# Display_Subsystem register map
Vendor: Texas Instruments
Peripheral module from a debugger description file (folder omap36xx).
Registers are 32-bit, read-only, reset 0x0 unless marked. A register's access mark holds for its fields unless they carry their own. Offsets are as the file gives them; lines under a group give offsets from that group; [hi:lo] are bit positions; {n}, {i} and the like mark numbered series; 'fields as' and 'values as' point back to an identical list; <NAME> marks a mode.

## Display_Subsystem
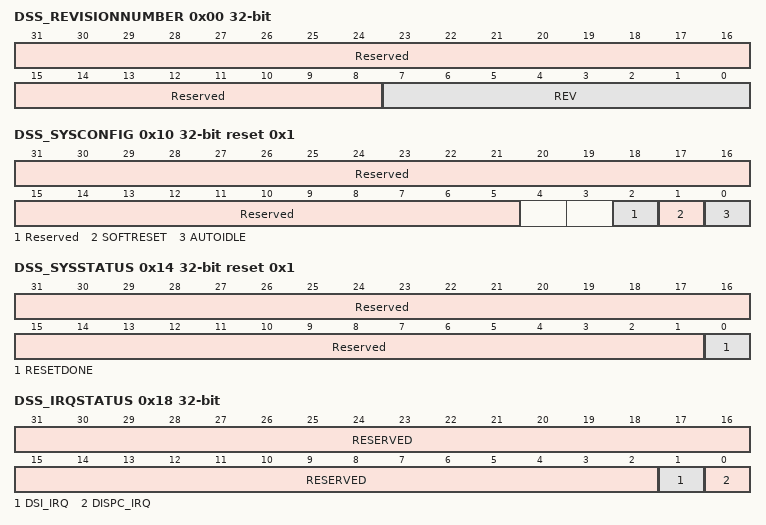
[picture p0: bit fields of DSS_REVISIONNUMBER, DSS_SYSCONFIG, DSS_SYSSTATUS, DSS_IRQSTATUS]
0x00 DSS_REVISIONNUMBER (reset mask 0xFFFFFF00) — This register contains the display subsystem revision number.
  [31:8] Reserved — Read returns 0.
  [7:0] REV — Revision number[7:4] Major revision[3:0] Minor revision
0x10 DSS_SYSCONFIG rw reset 0x1 — This register controls the various parameters of the interconnect interface.
  [31:5] Reserved — Write 0s for future compatibility. Reads return zero.
  [2] Reserved — Write 0s for future compatibility . Reads return zero.
  [1] SOFTRESET — Software reset. Set this bit to 1 to trigger a module reset. The bit is automatically reset by the hardware. During reads, it always returns 0.
    0=Normal mode; 1=The module is reset
  [0] AUTOIDLE — Enable power management capability
    0=OCP clock is free-running; 1=Automatic OCP clock gating strategy is applied based on the OCP interface activity
0x14 DSS_SYSSTATUS reset 0x1 — This register provides status information about the module.
  [31:1] Reserved — Read returns 0.
  [0] RESETDONE — Internal reset monitoring
    0=RESETDONE_0_r (Internal module reset is ongoing.); 1=RESETDONE_1_r (Reset completed)
0x18 DSS_IRQSTATUS — The register indicates the source of the interrupt and the status of the interrupt line.
  [31:2] RESERVED — Reads returns 0.
  [1] DSI_IRQ — DSI interrupt status (related toDSI_IRQSTATUS)
    0=DSI interrupt inactive; 1=DSI interrupt active
  [0] DISPC_IRQ — DISPC interrupt status (related toDISPC_IRQSTATUS)
    0=DISPC interrupt inactive; 1=DISPC interrupt active
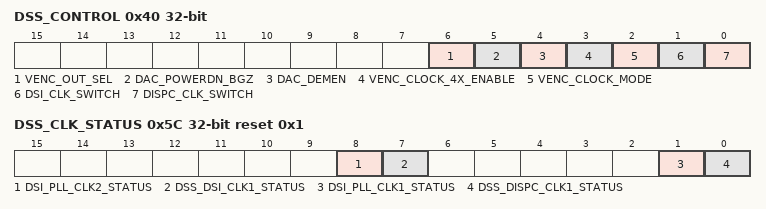
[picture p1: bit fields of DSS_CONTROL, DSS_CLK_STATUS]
0x40 DSS_CONTROL rw — This register contains the display subsystem control bits.
  [6] VENC_OUT_SEL — Video DAC1 input selection:0x0: CVBS VENC output selected for composite video mode0x1: Luminance VENC output selected for s-video mode
  [5] DAC_POWERDN_BGZ — DAC Power-Down Control0x0: DAC Power-Down Band Gap powered down0x1: DAC Power-Down Band Gap powered up
  [4] DAC_DEMEN — DAC dynamic element matching enable0x0: DAC Dynamic Element Matching Disabled 0x1: DAC Dynamic Element Matching Enabled
  [3] VENC_CLOCK_4X_ENABLE — VENC clock 4x enable0x0: Disable 0x1: Enable
  [2] VENC_CLOCK_MODE — VENC clock mode. See, . 0x0: Mode 0. All three balanced clocks, derived from the DSS_TV_CLK clock, are provided to the VENC, if the VENC_CLOCK_4X_ENABLE bit [3] is set to 1 by software. 0x1: Mode 1. The VENC_CLOCK_4X_ENABLE bit [3] is used to control clock gating.
  [1] DSI_CLK_SWITCH — Selects the clock source for the DSI functional clock0x0: DSS1_ALWON_FCLK clock is selected (from PRCM)0x1: DSI2_PLL_FCLK clock is selected (from DSI PLL)
  [0] DISPC_CLK_SWITCH — Selects the clock source for the DISPC functional clock0x0: DSS1_ALWON_FCLK clock is selected (from PRCM)0x1: DSI1_PLL_FCLK clock is selected (from DSI PLL)
0x5C DSS_CLK_STATUS reset 0x1 — This register contains the display subsystem register.
  [8] DSI_PLL_CLK2_STATUS — DSI2_PLL_FCLK clock selection status (DSI mux) Indicates if the DSI protocol engine is running from the DSI2_PLL_FCLK clockRead 0: DSI2_PLL_FCLK is not selected (unused by DSI).Read 1: DSI2_PLL_FCLK is selected (used by DSI).
  [7] DSS_DSI_CLK1_STATUS — DSS1_ALWON_FCLK clock selection status (DSI mux) Indicates if the DSI protocol engine is running from the DSS1_ALWON_FCLK clockRead 0: DSS1_ALWON_FCLK is not selected (unused by DSI).Read 1: DSS1_ALWON_FCLK is selected (used by DSI).
  [1] DSI_PLL_CLK1_STATUS — DSI1_PLL_FCLK clock selection status (DISPC mux) Indicates if the display controller is running from the DSI1_PLL_FCLK clockRead 0: DSI1_PLL_FCLK is not selected (unused by DISPC).Read 1: DSI1_PLL_FCLK is selected (used by DISPC).
  [0] DSS_DISPC_CLK1_STATUS — DSS1_ALWON_FCLK clock selection status (DISPC mux) Indicates if the display controller is running from the DSS1_ALWON_FCLK clockRead 0: DSS1_ALWON_FCLK is not selected (unused by DISPC).Read 1: DSS1_ALWON_FCLK is selected (used by DISPC).
